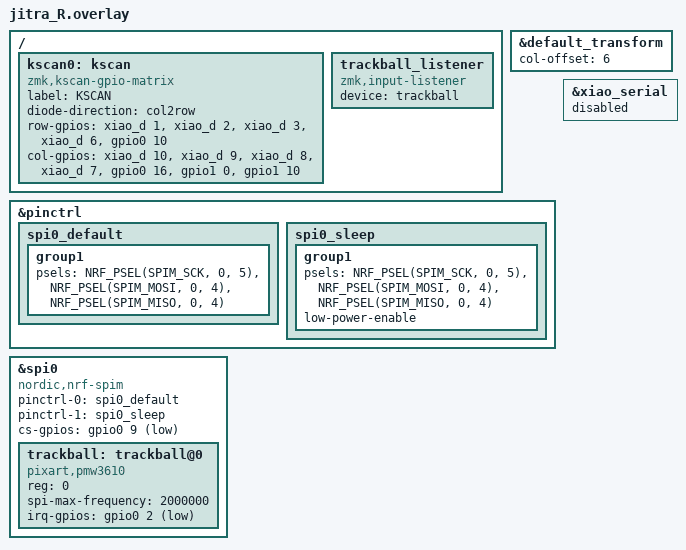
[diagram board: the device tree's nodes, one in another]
#include "jitra.dtsi"

&default_transform {
    col-offset = <6>;
};

/{
    kscan0: kscan {
        compatible = "zmk,kscan-gpio-matrix";
        label = "KSCAN";
        diode-direction = "col2row";

        row-gpios
            = <&xiao_d 1 (GPIO_ACTIVE_HIGH | GPIO_PULL_DOWN)>       /* Row0 = P0.03 (D1) */
            , <&xiao_d 2 (GPIO_ACTIVE_HIGH | GPIO_PULL_DOWN)>       /* Row1 = P0.28 (D2) */
            , <&xiao_d 3 (GPIO_ACTIVE_HIGH | GPIO_PULL_DOWN)>       /* Row2 = P0.29 (D3) */
            , <&xiao_d 6 (GPIO_ACTIVE_HIGH | GPIO_PULL_DOWN)>       /* Row3 = P1.11 (D6/TX) */
            , <&gpio0 10 (GPIO_ACTIVE_HIGH | GPIO_PULL_DOWN)>       /* Row4 = NFC2 (P0.10) */
            ;

        col-gpios
            = <&xiao_d 10 GPIO_ACTIVE_HIGH>  /* Col0 = P1.15 (D10/MOSI) */
            , <&xiao_d 9 GPIO_ACTIVE_HIGH>   /* Col1 = P1.14 (D9/MISO) */
            , <&xiao_d 8 GPIO_ACTIVE_HIGH>   /* Col2 = P1.13 (D8/SCK) */
            , <&xiao_d 7 GPIO_ACTIVE_HIGH>   /* Col3 = P1.12 (D7/RX) */
            , <&gpio0 16 GPIO_ACTIVE_HIGH>   /* Col4 = NFC3 (P0.16) */
            , <&gpio1 0 GPIO_ACTIVE_HIGH>    /* Col5 = NFC4 (P1.00) */
            , <&gpio1 10 GPIO_ACTIVE_HIGH>   /* Col6 = NFC5 (P1.10) */
            ;
    };

    trackball_listener {
        status = "okay";
        compatible = "zmk,input-listener";
        device = <&trackball>;
    };
};

&pinctrl {
    spi0_default: spi0_default {
        group1 {
            psels = <NRF_PSEL(SPIM_SCK, 0, 5)>,
                <NRF_PSEL(SPIM_MOSI, 0, 4)>,
                <NRF_PSEL(SPIM_MISO, 0, 4)>;
        };
    };

    spi0_sleep: spi0_sleep {
        group1 {
            psels = <NRF_PSEL(SPIM_SCK, 0, 5)>,
                <NRF_PSEL(SPIM_MOSI, 0, 4)>,
                <NRF_PSEL(SPIM_MISO, 0, 4)>;
            low-power-enable;
        };
    };
};

&xiao_serial { status = "disabled"; };

&spi0 {
    status = "okay";
    compatible = "nordic,nrf-spim";
    pinctrl-0 = <&spi0_default>;
    pinctrl-1 = <&spi0_sleep>;
    pinctrl-names = "default", "sleep";
    cs-gpios = <&gpio0 9 GPIO_ACTIVE_LOW>;  /* CS = NFC1 (P0.09) */

    trackball: trackball@0 {
        status = "okay";
        compatible = "pixart,pmw3610";
        reg = <0>;
        spi-max-frequency = <2000000>;
        irq-gpios = <&gpio0 2 (GPIO_ACTIVE_LOW | GPIO_PULL_UP)>;  /* MOTION = P0.02 (D0) */
    };
};
